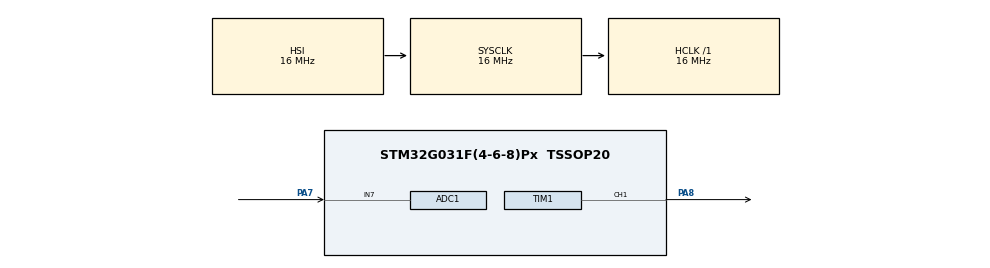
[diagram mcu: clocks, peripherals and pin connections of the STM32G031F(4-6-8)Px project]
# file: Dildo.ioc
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ADC1.Channel-0\#ChannelRegularConversion=ADC_CHANNEL_7
ADC1.ExternalTrigConv=ADC_EXTERNALTRIG_T1_TRGO2
ADC1.NbrOfConversionFlag=1
ADC1.Rank-0\#ChannelRegularConversion=1
ADC1.SamplingTime-0\#ChannelRegularConversion=ADC_SAMPLINGTIME_COMMON_1
ADC1.master=1
Mcu.Family=STM32G0
Mcu.Name=STM32G031F(4-6-8)Px
Mcu.Package=TSSOP20
NVIC.ADC1_IRQn=true\:0\:0\:false\:false\:true\:true\:true
PA13.Mode=Serial_Wire
PA13.Signal=SYS_SWDIO
PA14-BOOT0.Mode=Serial_Wire
PA14-BOOT0.Signal=SYS_SWCLK
PA7.Mode=IN7
PA7.Signal=ADC1_IN7
PA8.Signal=S_TIM1_CH1
ProjectManager.HeapSize=0x200
ProjectManager.StackSize=0x400
ProjectManager.TargetToolchain=STM32CubeIDE
RCC.AHBFreq_Value=16000000
RCC.CortexFreq_Value=16000000
RCC.EXTERNAL_CLOCK_VALUE=12288000
RCC.HCLKFreq_Value=16000000
RCC.HSE_VALUE=8000000
RCC.HSI_VALUE=16000000
RCC.LSE_VALUE=32768
RCC.SYSCLKFreq_VALUE=16000000
RCC.VCOOutputFreq_Value=128000000
SH.S_TIM1_CH1.0=TIM1_CH1,PWM Generation1 CH1
TIM1.Channel-PWM\ Generation1\ CH1=TIM_CHANNEL_1
TIM1.Period=200
TIM1.Prescaler=8000
TIM1.Pulse-PWM\ Generation1\ CH1=100
TIM1.TIM_MasterOutputTrigger2=TIM_TRGO2_OC1
VP_TIM1_VS_ClockSourceINT.Mode=Internal
board=custom

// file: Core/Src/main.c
/* USER CODE BEGIN Header */
/**
  ******************************************************************************
  * @file           : main.c
  * @brief          : Main program body
  ******************************************************************************
  * @attention
  *
  * <h2><center>&copy; Copyright (c) 2020 STMicroelectronics.
  * All rights reserved.</center></h2>
  *
  * This software component is licensed by ST under BSD 3-Clause license,
  * the "License"; You may not use this file except in compliance with the
  * License. You may obtain a copy of the License at:
  *                        opensource.org/licenses/BSD-3-Clause
  *
  ******************************************************************************
  */
/* USER CODE END Header */

#include "main.h"

ADC_HandleTypeDef hadc1;

TIM_HandleTypeDef htim1;

void SystemClock_Config(void);
static void MX_GPIO_Init(void);
static void MX_TIM1_Init(void);
static void MX_ADC1_Init(void);

/* USER CODE BEGIN 0 */
uint32_t	adc_val;
void adc_conversion_complete(void)
{
	adc_val = HAL_ADC_GetValue(&hadc1);
}
/* USER CODE END 0 */

int main(void)
{

  /* MCU Configuration--------------------------------------------------------*/

  /* Reset of all peripherals, Initializes the Flash interface and the Systick. */
  HAL_Init();

  /* Configure the system clock */
  SystemClock_Config();

  /* Initialize all configured peripherals */
  MX_GPIO_Init();
  MX_TIM1_Init();
  MX_ADC1_Init();
  /* USER CODE BEGIN 2 */
  HAL_TIM_PWM_Start(&htim1, TIM_CHANNEL_1);
  HAL_ADC_Start_IT(&hadc1);
  /* USER CODE END 2 */

  /* Infinite loop */
  while (1)
  {

  }
}

void SystemClock_Config(void)
{
  RCC_OscInitTypeDef RCC_OscInitStruct = {0};
  RCC_ClkInitTypeDef RCC_ClkInitStruct = {0};
  RCC_PeriphCLKInitTypeDef PeriphClkInit = {0};

  /** Configure the main internal regulator output voltage
  */
  HAL_PWREx_ControlVoltageScaling(PWR_REGULATOR_VOLTAGE_SCALE1);
  /** Initializes the CPU, AHB and APB busses clocks
  */
  RCC_OscInitStruct.OscillatorType = RCC_OSCILLATORTYPE_HSI;
  RCC_OscInitStruct.HSIState = RCC_HSI_ON;
  RCC_OscInitStruct.HSIDiv = RCC_HSI_DIV1;
  RCC_OscInitStruct.HSICalibrationValue = RCC_HSICALIBRATION_DEFAULT;
  RCC_OscInitStruct.PLL.PLLState = RCC_PLL_NONE;
  if (HAL_RCC_OscConfig(&RCC_OscInitStruct) != HAL_OK)
  {
    Error_Handler();
  }
  /** Initializes the CPU, AHB and APB busses clocks
  */
  RCC_ClkInitStruct.ClockType = RCC_CLOCKTYPE_HCLK|RCC_CLOCKTYPE_SYSCLK
                              |RCC_CLOCKTYPE_PCLK1;
  RCC_ClkInitStruct.SYSCLKSource = RCC_SYSCLKSOURCE_HSI;
  RCC_ClkInitStruct.AHBCLKDivider = RCC_SYSCLK_DIV1;
  RCC_ClkInitStruct.APB1CLKDivider = RCC_HCLK_DIV1;

  if (HAL_RCC_ClockConfig(&RCC_ClkInitStruct, FLASH_LATENCY_0) != HAL_OK)
  {
    Error_Handler();
  }
  /** Initializes the peripherals clocks
  */
  PeriphClkInit.PeriphClockSelection = RCC_PERIPHCLK_ADC|RCC_PERIPHCLK_TIM1;
  PeriphClkInit.AdcClockSelection = RCC_ADCCLKSOURCE_SYSCLK;
  PeriphClkInit.Tim1ClockSelection = RCC_TIM1CLKSOURCE_PCLK1;
  if (HAL_RCCEx_PeriphCLKConfig(&PeriphClkInit) != HAL_OK)
  {
    Error_Handler();
  }
}

static void MX_ADC1_Init(void)
{

  ADC_ChannelConfTypeDef sConfig = {0};

  /** Configure the global features of the ADC (Clock, Resolution, Data Alignment and number of conversion)
  */
  hadc1.Instance = ADC1;
  hadc1.Init.ClockPrescaler = ADC_CLOCK_SYNC_PCLK_DIV2;
  hadc1.Init.Resolution = ADC_RESOLUTION_12B;
  hadc1.Init.DataAlign = ADC_DATAALIGN_RIGHT;
  hadc1.Init.ScanConvMode = ADC_SCAN_DISABLE;
  hadc1.Init.EOCSelection = ADC_EOC_SINGLE_CONV;
  hadc1.Init.LowPowerAutoWait = DISABLE;
  hadc1.Init.LowPowerAutoPowerOff = DISABLE;
  hadc1.Init.ContinuousConvMode = DISABLE;
  hadc1.Init.NbrOfConversion = 1;
  hadc1.Init.DiscontinuousConvMode = DISABLE;
  hadc1.Init.ExternalTrigConv = ADC_EXTERNALTRIG_T1_TRGO2;
  hadc1.Init.ExternalTrigConvEdge = ADC_EXTERNALTRIGCONVEDGE_RISING;
  hadc1.Init.DMAContinuousRequests = DISABLE;
  hadc1.Init.Overrun = ADC_OVR_DATA_PRESERVED;
  hadc1.Init.SamplingTimeCommon1 = ADC_SAMPLETIME_1CYCLE_5;
  hadc1.Init.SamplingTimeCommon2 = ADC_SAMPLETIME_1CYCLE_5;
  hadc1.Init.OversamplingMode = DISABLE;
  hadc1.Init.TriggerFrequencyMode = ADC_TRIGGER_FREQ_HIGH;
  if (HAL_ADC_Init(&hadc1) != HAL_OK)
  {
    Error_Handler();
  }
  /** Configure Regular Channel
  */
  sConfig.Channel = ADC_CHANNEL_7;
  sConfig.Rank = ADC_REGULAR_RANK_1;
  sConfig.SamplingTime = ADC_SAMPLINGTIME_COMMON_1;
  if (HAL_ADC_ConfigChannel(&hadc1, &sConfig) != HAL_OK)
  {
    Error_Handler();
  }

}

static void MX_TIM1_Init(void)
{

  TIM_ClockConfigTypeDef sClockSourceConfig = {0};
  TIM_MasterConfigTypeDef sMasterConfig = {0};
  TIM_OC_InitTypeDef sConfigOC = {0};
  TIM_BreakDeadTimeConfigTypeDef sBreakDeadTimeConfig = {0};

  htim1.Instance = TIM1;
  htim1.Init.Prescaler = 8000;
  htim1.Init.CounterMode = TIM_COUNTERMODE_UP;
  htim1.Init.Period = 200;
  htim1.Init.ClockDivision = TIM_CLOCKDIVISION_DIV1;
  htim1.Init.RepetitionCounter = 0;
  htim1.Init.AutoReloadPreload = TIM_AUTORELOAD_PRELOAD_DISABLE;
  if (HAL_TIM_Base_Init(&htim1) != HAL_OK)
  {
    Error_Handler();
  }
  sClockSourceConfig.ClockSource = TIM_CLOCKSOURCE_INTERNAL;
  if (HAL_TIM_ConfigClockSource(&htim1, &sClockSourceConfig) != HAL_OK)
  {
    Error_Handler();
  }
  if (HAL_TIM_PWM_Init(&htim1) != HAL_OK)
  {
    Error_Handler();
  }
  sMasterConfig.MasterOutputTrigger = TIM_TRGO_RESET;
  sMasterConfig.MasterOutputTrigger2 = TIM_TRGO2_OC1;
  sMasterConfig.MasterSlaveMode = TIM_MASTERSLAVEMODE_DISABLE;
  if (HAL_TIMEx_MasterConfigSynchronization(&htim1, &sMasterConfig) != HAL_OK)
  {
    Error_Handler();
  }
  sConfigOC.OCMode = TIM_OCMODE_PWM1;
  sConfigOC.Pulse = 100;
  sConfigOC.OCPolarity = TIM_OCPOLARITY_HIGH;
  sConfigOC.OCNPolarity = TIM_OCNPOLARITY_HIGH;
  sConfigOC.OCFastMode = TIM_OCFAST_DISABLE;
  sConfigOC.OCIdleState = TIM_OCIDLESTATE_RESET;
  sConfigOC.OCNIdleState = TIM_OCNIDLESTATE_RESET;
  if (HAL_TIM_PWM_ConfigChannel(&htim1, &sConfigOC, TIM_CHANNEL_1) != HAL_OK)
  {
    Error_Handler();
  }
  sBreakDeadTimeConfig.OffStateRunMode = TIM_OSSR_DISABLE;
  sBreakDeadTimeConfig.OffStateIDLEMode = TIM_OSSI_DISABLE;
  sBreakDeadTimeConfig.LockLevel = TIM_LOCKLEVEL_OFF;
  sBreakDeadTimeConfig.DeadTime = 0;
  sBreakDeadTimeConfig.BreakState = TIM_BREAK_DISABLE;
  sBreakDeadTimeConfig.BreakPolarity = TIM_BREAKPOLARITY_HIGH;
  sBreakDeadTimeConfig.BreakFilter = 0;
  sBreakDeadTimeConfig.BreakAFMode = TIM_BREAK_AFMODE_INPUT;
  sBreakDeadTimeConfig.Break2State = TIM_BREAK2_DISABLE;
  sBreakDeadTimeConfig.Break2Polarity = TIM_BREAK2POLARITY_HIGH;
  sBreakDeadTimeConfig.Break2Filter = 0;
  sBreakDeadTimeConfig.Break2AFMode = TIM_BREAK_AFMODE_INPUT;
  sBreakDeadTimeConfig.AutomaticOutput = TIM_AUTOMATICOUTPUT_DISABLE;
  if (HAL_TIMEx_ConfigBreakDeadTime(&htim1, &sBreakDeadTimeConfig) != HAL_OK)
  {
    Error_Handler();
  }
  HAL_TIM_MspPostInit(&htim1);

}

static void MX_GPIO_Init(void)
{

  /* GPIO Ports Clock Enable */
  __HAL_RCC_GPIOA_CLK_ENABLE();

}

void Error_Handler(void)
{
}

/************************ (C) COPYRIGHT STMicroelectronics *****END OF FILE****/
